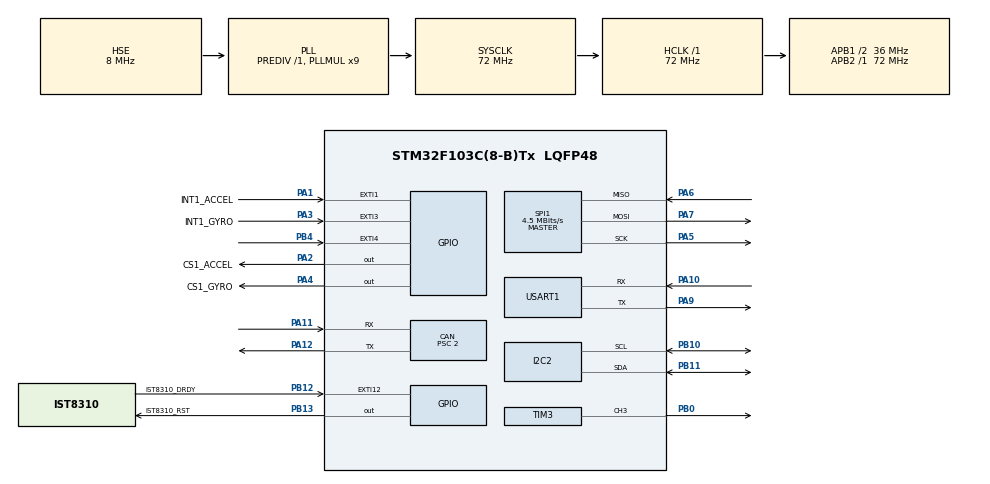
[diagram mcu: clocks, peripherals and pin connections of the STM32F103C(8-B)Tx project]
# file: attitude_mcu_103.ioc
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CAN.ABOM=ENABLE
CAN.AWUM=ENABLE
CAN.BS1=CAN_BS1_13TQ
CAN.BS2=CAN_BS2_4TQ
CAN.CalculateBaudRate=1000000
CAN.CalculateTimeBit=1000
CAN.CalculateTimeQuantum=55.55555555555556
CAN.Prescaler=2
CAN.RFLM=DISABLE
Dma.Request0=SPI1_RX
Dma.Request1=SPI1_TX
Dma.SPI1_RX.0.Direction=DMA_PERIPH_TO_MEMORY
Dma.SPI1_RX.0.Instance=DMA1_Channel2
Dma.SPI1_RX.0.MemDataAlignment=DMA_MDATAALIGN_BYTE
Dma.SPI1_RX.0.MemInc=DMA_MINC_ENABLE
Dma.SPI1_RX.0.Mode=DMA_NORMAL
Dma.SPI1_RX.0.PeriphDataAlignment=DMA_PDATAALIGN_BYTE
Dma.SPI1_RX.0.PeriphInc=DMA_PINC_DISABLE
Dma.SPI1_RX.0.Priority=DMA_PRIORITY_VERY_HIGH
Dma.SPI1_TX.1.Direction=DMA_MEMORY_TO_PERIPH
Dma.SPI1_TX.1.Instance=DMA1_Channel3
Dma.SPI1_TX.1.MemDataAlignment=DMA_MDATAALIGN_BYTE
Dma.SPI1_TX.1.MemInc=DMA_MINC_ENABLE
Dma.SPI1_TX.1.Mode=DMA_NORMAL
Dma.SPI1_TX.1.PeriphDataAlignment=DMA_PDATAALIGN_BYTE
Dma.SPI1_TX.1.PeriphInc=DMA_PINC_DISABLE
Dma.SPI1_TX.1.Priority=DMA_PRIORITY_HIGH
I2C2.I2C_Mode=I2C_Fast
Mcu.Family=STM32F1
Mcu.Name=STM32F103C(8-B)Tx
Mcu.Package=LQFP48
NVIC.DMA1_Channel2_IRQn=true\:5\:0\:true\:false\:false\:false\:true\:true
NVIC.DMA1_Channel3_IRQn=true\:5\:0\:true\:false\:false\:false\:true\:true
NVIC.EXTI15_10_IRQn=true\:5\:0\:true\:false\:true\:true\:true\:true
NVIC.EXTI1_IRQn=true\:5\:0\:true\:false\:true\:true\:true\:true
NVIC.EXTI3_IRQn=true\:5\:0\:true\:false\:true\:true\:true\:true
NVIC.EXTI4_IRQn=true\:6\:0\:true\:false\:true\:true\:true\:true
NVIC.PriorityGroup=NVIC_PRIORITYGROUP_4
NVIC.USB_LP_CAN1_RX0_IRQn=true\:0\:0\:false\:false\:true\:true\:true\:true
PA1.GPIO_Label=INT1_ACCEL
PA1.GPIO_ModeDefaultEXTI=GPIO_MODE_IT_FALLING
PA1.GPIO_PuPd=GPIO_PULLUP
PA1.Signal=GPXTI1
PA10.Mode=Asynchronous
PA10.Signal=USART1_RX
PA11.GPIO_PuPd=GPIO_NOPULL
PA11.Mode=CAN_Activate
PA11.Signal=CAN_RX
PA12.GPIO_Speed=GPIO_SPEED_FREQ_HIGH
PA12.Mode=CAN_Activate
PA12.Signal=CAN_TX
PA13.Mode=Serial_Wire
PA13.Signal=SYS_JTMS-SWDIO
PA14.Mode=Serial_Wire
PA14.Signal=SYS_JTCK-SWCLK
PA2.GPIO_Label=CS1_ACCEL
PA2.GPIO_PuPd=GPIO_PULLUP
PA2.GPIO_Speed=GPIO_SPEED_FREQ_HIGH
PA2.PinState=GPIO_PIN_SET
PA2.Signal=GPIO_Output
PA3.GPIO_Label=INT1_GYRO
PA3.GPIO_ModeDefaultEXTI=GPIO_MODE_IT_FALLING
PA3.GPIO_PuPd=GPIO_PULLUP
PA3.Signal=GPXTI3
PA4.GPIO_Label=CS1_GYRO
PA4.GPIO_PuPd=GPIO_PULLUP
PA4.GPIO_Speed=GPIO_SPEED_FREQ_HIGH
PA4.PinState=GPIO_PIN_SET
PA4.Signal=GPIO_Output
PA5.GPIO_Speed=GPIO_SPEED_FREQ_HIGH
PA5.Mode=Full_Duplex_Master
PA5.Signal=SPI1_SCK
PA6.GPIO_Mode=GPIO_MODE_INPUT
PA6.Mode=Full_Duplex_Master
PA6.Signal=SPI1_MISO
PA7.GPIO_Speed=GPIO_SPEED_FREQ_HIGH
PA7.Mode=Full_Duplex_Master
PA7.Signal=SPI1_MOSI
PA9.Mode=Asynchronous
PA9.Signal=USART1_TX
PB0.Signal=S_TIM3_CH3
PB10.Mode=I2C
PB10.Signal=I2C2_SCL
PB11.Mode=I2C
PB11.Signal=I2C2_SDA
PB12.GPIO_Label=IST8310_DRDY
PB12.GPIO_ModeDefaultEXTI=GPIO_MODE_IT_FALLING
PB12.GPIO_PuPd=GPIO_PULLUP
PB12.Signal=GPXTI12
PB13.GPIO_Label=IST8310_RST
PB13.GPIO_PuPd=GPIO_PULLUP
PB13.GPIO_Speed=GPIO_SPEED_FREQ_MEDIUM
PB13.PinState=GPIO_PIN_SET
PB13.Signal=GPIO_Output
PB4.GPIO_ModeDefaultEXTI=GPIO_MODE_IT_FALLING
PB4.GPIO_PuPd=GPIO_PULLUP
PB4.Signal=GPXTI4
PD0-OSC_IN.Mode=HSE-External-Oscillator
PD0-OSC_IN.Signal=RCC_OSC_IN
PD1-OSC_OUT.Mode=HSE-External-Oscillator
PD1-OSC_OUT.Signal=RCC_OSC_OUT
ProjectManager.HeapSize=0x200
ProjectManager.StackSize=0x400
ProjectManager.TargetToolchain=MDK-ARM V5
RCC.AHBFreq_Value=72000000
RCC.APB1CLKDivider=RCC_HCLK_DIV2
RCC.APB1Freq_Value=36000000
RCC.APB1TimFreq_Value=72000000
RCC.APB2Freq_Value=72000000
RCC.APB2TimFreq_Value=72000000
RCC.HCLKFreq_Value=72000000
RCC.PLLMUL=RCC_PLL_MUL9
RCC.PLLSourceVirtual=RCC_PLLSOURCE_HSE
RCC.SYSCLKFreq_VALUE=72000000
RCC.SYSCLKSource=RCC_SYSCLKSOURCE_PLLCLK
RCC.USBFreq_Value=72000000
SH.S_TIM3_CH3.0=TIM3_CH3,PWM Generation3 CH3
SPI1.BaudRatePrescaler=SPI_BAUDRATEPRESCALER_16
SPI1.CLKPhase=SPI_PHASE_2EDGE
SPI1.CLKPolarity=SPI_POLARITY_HIGH
SPI1.CalculateBaudRate=4.5 MBits/s
SPI1.Direction=SPI_DIRECTION_2LINES
SPI1.Mode=SPI_MODE_MASTER
SPI1.VirtualType=VM_MASTER
TIM3.AutoReloadPreload=TIM_AUTORELOAD_PRELOAD_ENABLE
TIM3.Channel-PWM\ Generation3\ CH3=TIM_CHANNEL_3
TIM3.Period=4999
USART1.VirtualMode=VM_ASYNC
board=custom

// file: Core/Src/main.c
/* USER CODE BEGIN Header */
/**
  ******************************************************************************
  * @file           : main.c
  * @brief          : Main program body
  ******************************************************************************
  * @attention
  *
  * Copyright (c) 2023 STMicroelectronics.
  * All rights reserved.
  *
  * This software is licensed under terms that can be found in the LICENSE file
  * in the root directory of this software component.
  * If no LICENSE file comes with this software, it is provided AS-IS.
  *
  ******************************************************************************
  */
/* USER CODE END Header */
#include "main.h"
#include "can.h"
#include "dma.h"
#include "i2c.h"
#include "spi.h"
#include "tim.h"
#include "usart.h"
#include "gpio.h"

/* USER CODE BEGIN Includes */
#include "INS_task.h"
#include "dwt.h"
/* USER CODE END Includes */

void SystemClock_Config(void);

int main(void)
{

  /* MCU Configuration--------------------------------------------------------*/

  /* Reset of all peripherals, Initializes the Flash interface and the Systick. */
  HAL_Init();

  /* Configure the system clock */
  SystemClock_Config();

  /* Initialize all configured peripherals */
  MX_GPIO_Init();
  MX_DMA_Init();
  MX_SPI1_Init();
  MX_I2C2_Init();
  MX_TIM3_Init();
  MX_USART1_UART_Init();
  MX_CAN_Init();
  /* USER CODE BEGIN 2 */
	DWT_INIT(MY_MCU_SYSCLK);
	INS_init();
  /* USER CODE END 2 */

  /* Infinite loop */
  while (1)
  {

    /* USER CODE BEGIN 3 */
    INS_task();

  }
  /* USER CODE END 3 */
}

void SystemClock_Config(void)
{
  RCC_OscInitTypeDef RCC_OscInitStruct = {0};
  RCC_ClkInitTypeDef RCC_ClkInitStruct = {0};

  /** Initializes the RCC Oscillators according to the specified parameters
  * in the RCC_OscInitTypeDef structure.
  */
  RCC_OscInitStruct.OscillatorType = RCC_OSCILLATORTYPE_HSE;
  RCC_OscInitStruct.HSEState = RCC_HSE_ON;
  RCC_OscInitStruct.HSEPredivValue = RCC_HSE_PREDIV_DIV1;
  RCC_OscInitStruct.HSIState = RCC_HSI_ON;
  RCC_OscInitStruct.PLL.PLLState = RCC_PLL_ON;
  RCC_OscInitStruct.PLL.PLLSource = RCC_PLLSOURCE_HSE;
  RCC_OscInitStruct.PLL.PLLMUL = RCC_PLL_MUL9;
  if (HAL_RCC_OscConfig(&RCC_OscInitStruct) != HAL_OK)
  {
    Error_Handler();
  }

  /** Initializes the CPU, AHB and APB buses clocks
  */
  RCC_ClkInitStruct.ClockType = RCC_CLOCKTYPE_HCLK|RCC_CLOCKTYPE_SYSCLK
                              |RCC_CLOCKTYPE_PCLK1|RCC_CLOCKTYPE_PCLK2;
  RCC_ClkInitStruct.SYSCLKSource = RCC_SYSCLKSOURCE_PLLCLK;
  RCC_ClkInitStruct.AHBCLKDivider = RCC_SYSCLK_DIV1;
  RCC_ClkInitStruct.APB1CLKDivider = RCC_HCLK_DIV2;
  RCC_ClkInitStruct.APB2CLKDivider = RCC_HCLK_DIV1;

  if (HAL_RCC_ClockConfig(&RCC_ClkInitStruct, FLASH_LATENCY_2) != HAL_OK)
  {
    Error_Handler();
  }
}

void Error_Handler(void)
{
  __disable_irq();
  while (1)
  {
  }
}
